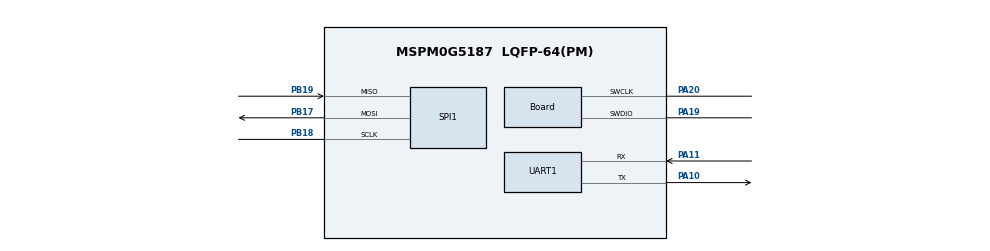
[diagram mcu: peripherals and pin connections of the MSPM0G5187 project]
//@cliArgs --device "MSPM0G518X" --package "LQFP-64(PM)" --part "Default"
//@v2CliArgs --device "MSPM0G5187" --package "LQFP-64(PM)"
// @cliArgs --board /ti/boards/LP_MSPM0G5187 --rtos nortos

/**
 * Import the modules used in this configuration.
 */
const GPIO  = scripting.addModule("/ti/driverlib/GPIO", {}, false);
const GPIO1 = GPIO.addInstance();
const GPIO2 = GPIO.addInstance();
const SPI   = scripting.addModule("/ti/driverlib/SPI", {}, false);
const SPI1  = SPI.addInstance();
const UART  = scripting.addModule("/ti/driverlib/UART", {}, false);
const UART1 = UART.addInstance();

/**
 * Write custom configuration values to the imported modules.
 */
const divider7       = system.clockTree["PLL_PDIV"];
divider7.divideValue = 2;

const divider9       = system.clockTree["UDIV"];
divider9.divideValue = 2;

const multiplier2         = system.clockTree["PLL_QDIV"];
multiplier2.multiplyValue = 5;

const mux7       = system.clockTree["HSCLKMUX"];
mux7.inputSelect = "HSCLKMUX_SYSPLL2X";

GPIO1.$name                              = "SPI";
GPIO1.associatedPins[0].initialValue     = "SET";
GPIO1.associatedPins[0].internalResistor = "PULL_UP";
GPIO1.associatedPins[0].$name            = "CS_0";
GPIO1.associatedPins[0].assignedPort     = "PORTB";
GPIO1.associatedPins[0].assignedPin      = "0";

const Board                       = scripting.addModule("/ti/driverlib/Board", {}, false);
Board.peripheral.$assign          = "DEBUGSS";
Board.peripheral.swclkPin.$assign = "PA20";
Board.peripheral.swdioPin.$assign = "PA19";

GPIO2.$name                          = "SENSOR";
GPIO2.associatedPins[0].direction    = "INPUT";
GPIO2.associatedPins[0].interruptEn  = true;
GPIO2.associatedPins[0].$name        = "RDY_1";
GPIO2.associatedPins[0].assignedPort = "PORTA";
GPIO2.associatedPins[0].assignedPin  = "12";
GPIO2.associatedPins[0].polarity     = "RISE";

SPI1.$name                      = "SPI_0";
SPI1.chipSelect                 = ["1"];
SPI1.frameFormat                = "MOTO3";
SPI1.phase                      = "1";
SPI1.targetBitRate              = 1000000;
SPI1.peripheral.sclkPin.$assign = "PB18";
SPI1.peripheral.mosiPin.$assign = "PB17";
SPI1.peripheral.misoPin.$assign = "PB19";

const SYSCTL                 = scripting.addModule("/ti/driverlib/SYSCTL", {}, false);
SYSCTL.forceDefaultClkConfig = true;
SYSCTL.clockTreeEn           = true;

UART1.enabledDMARXTriggers              = "DL_UART_DMA_INTERRUPT_RX";
UART1.enabledDMATXTriggers              = "DL_UART_DMA_INTERRUPT_TX";
UART1.$name                             = "UART_DAP";
UART1.targetBaudRate                    = 115200;
UART1.peripheral.rxPin.$assign          = "PA11";
UART1.peripheral.txPin.$assign          = "PA10";
UART1.DMA_CHANNEL_RX.$name              = "DMA_CH0";
UART1.DMA_CHANNEL_RX.srcLength          = "BYTE";
UART1.DMA_CHANNEL_RX.dstLength          = "BYTE";
UART1.DMA_CHANNEL_RX.addressMode        = "f2b";
UART1.DMA_CHANNEL_RX.enableInterrupt    = true;
UART1.DMA_CHANNEL_RX.peripheral.$assign = "DMA_CH1";
UART1.DMA_CHANNEL_TX.$name              = "DMA_CH1";
UART1.DMA_CHANNEL_TX.srcLength          = "BYTE";
UART1.DMA_CHANNEL_TX.dstLength          = "BYTE";
UART1.DMA_CHANNEL_TX.addressMode        = "b2f";
UART1.DMA_CHANNEL_TX.enableInterrupt    = true;
UART1.DMA_CHANNEL_TX.peripheral.$assign = "DMA_CH0";

const ProjectConfig              = scripting.addModule("/ti/project_config/ProjectConfig", {}, false);
ProjectConfig.migrationCondition = true;
